# EFM32G8xx register map
File version: 2.7.3
CPU: CM3 r2p0, little endian, MPU, no FPU, 3 interrupt priority bits
Registers are 32-bit, read-write, reset 0x0 unless marked. A register's access mark holds for its fields unless they carry their own. Offsets are from the block's base; [hi:lo] are bit positions; {n}, {i} and the like mark numbered series.

## PRS
Base 0x400CC000
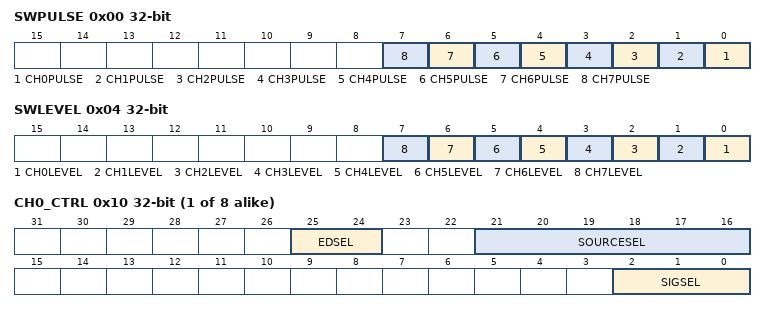
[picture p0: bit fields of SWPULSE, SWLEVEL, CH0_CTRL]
0x00 SWPULSE wo — Software Pulse Register
  [n] CH{n}PULSE (n=0..7) — Channel {n} Pulse Generation
0x04 SWLEVEL — Software Level Register
  [n] CH{n}LEVEL (n=0..7) — Channel {n} Software Level
{0x10+4i} CH{i}_CTRL (i=0..7) — Channel Control Register
  [25:24] EDSEL — Edge Detect Select
    0=OFF (Signal is left as it is); 1=POSEDGE (A one HFPERCLK cycle pulse is generated for every positive edge of the incoming signal); 2=NEGEDGE (A one HFPERCLK clock cycle pulse is generated for every negative edge of the incoming signal); 3=BOTHEDGES (A one HFPERCLK clock cycle pulse is generated for every edge of the incoming signal)
  [21:16] SOURCESEL — Source Select
    0=NONE (No source selected); 1=VCMP (Voltage Comparator); 2=ACMP0 (Analog Comparator 0); 3=ACMP1 (Analog Comparator 1); 6=DAC0 (Digital to Analog Converter 0); 8=ADC0 (Analog to Digital Converter 0); 16=USART0 (Universal Synchronous/Asynchronous Receiver/Transmitter 0); 17=USART1 (Universal Synchronous/Asynchronous Receiver/Transmitter 1); 18=USART2 (Universal Synchronous/Asynchronous Receiver/Transmitter 2); 28=TIMER0; 29=TIMER1; 30=TIMER2; 40=RTC (Real-Time Counter); 41=UART0 (Universal Asynchronous Receiver/Transmitter 0); 48=GPIOL (General purpose Input/Output); 49=GPIOH (General purpose Input/Output)
  [2:0] SIGSEL — Signal Select

## DAC0
Base 0x40004000
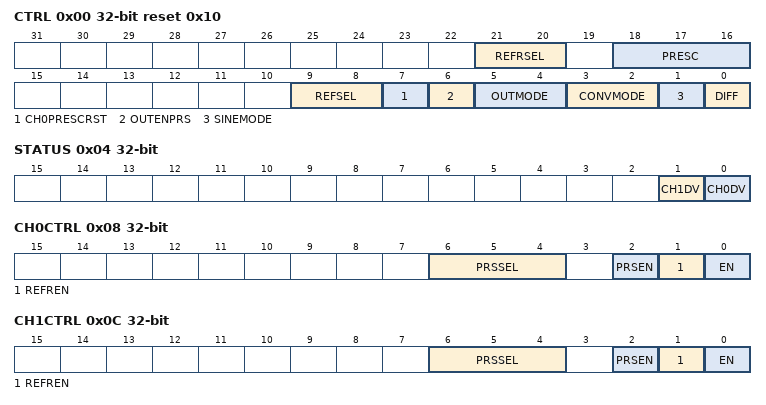
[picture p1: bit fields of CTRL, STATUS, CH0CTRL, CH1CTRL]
0x00 CTRL reset 0x10 — Control Register
  [21:20] REFRSEL — Refresh Interval Select
    0=8CYCLES (All channels with enabled refresh are refreshed every 8 prescaled cycles); 1=16CYCLES (All channels with enabled refresh are refreshed every 16 prescaled cycles); 2=32CYCLES (All channels with enabled refresh are refreshed every 32 prescaled cycles); 3=64CYCLES (All channels with enabled refresh are refreshed every 64 prescaled cycles)
  [18:16] PRESC — Prescaler Setting
    0=NODIVISION
  [9:8] REFSEL — Reference Selection
    0=1V25 (Internal 1.25 V bandgap reference); 1=2V5 (Internal 2.5 V bandgap reference); 2=VDD (VDD reference)
  [7] CH0PRESCRST — Channel 0 Start Reset Prescaler
  [6] OUTENPRS — PRS Controlled Output Enable
  [5:4] OUTMODE — Output Mode
    0=DISABLE (DAC output to pin and ADC disabled); 1=PIN (DAC output to pin enabled. DAC output to ADC disabled); 2=ADC (DAC output to pin disabled. DAC output to ADC enabled); 3=PINADC (DAC output to pin and ADC enabled)
  [3:2] CONVMODE — Conversion Mode
    0=CONTINUOUS (DAC is set in continuous mode); 1=SAMPLEHOLD (DAC is set in sample/hold mode); 2=SAMPLEOFF (DAC is set in sample/shut off mode)
  [1] SINEMODE
  [0] DIFF — Differential Mode
0x04 STATUS ro
  [1] CH1DV — Channel 1 Data Valid
  [0] CH0DV — Channel 0 Data Valid
0x08 CH0CTRL — Channel 0 Control Register
  [6:4] PRSSEL — Channel 0 PRS Trigger Select
    {v}=PRSCH{v} (PRS ch {v} triggers channel 0 conversion.) (v=0..7)
  [2] PRSEN — Channel 0 PRS Trigger Enable
  [1] REFREN — Channel 0 Automatic Refresh Enable
  [0] EN — Channel 0 Enable
0x0C CH1CTRL — Channel 1 Control Register
  [6:4] PRSSEL — Channel 1 PRS Trigger Select
    {v}=PRSCH{v} (PRS ch {v} triggers channel 1 conversion.) (v=0..7)
  [2] PRSEN — Channel 1 PRS Trigger Enable
  [1] REFREN — Channel 1 Automatic Refresh Enable
  [0] EN — Channel 1 Enable
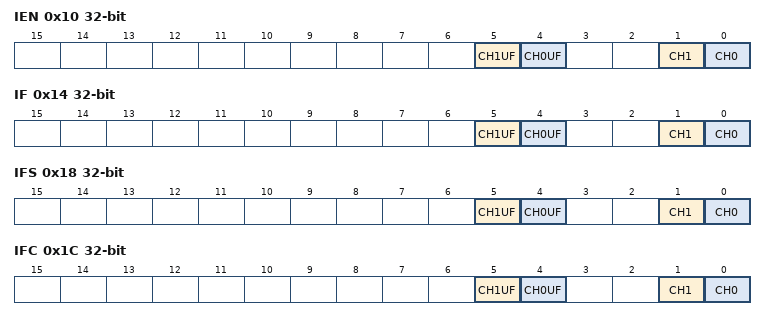
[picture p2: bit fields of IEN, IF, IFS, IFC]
0x10 IEN — Interrupt Enable Register
  [5] CH1UF — Channel 1 Conversion Data Underflow Interrupt Enable
  [4] CH0UF — Channel 0 Conversion Data Underflow Interrupt Enable
  [1] CH1 — Channel 1 Conversion Complete Interrupt Enable
  [0] CH0 — Channel 0 Conversion Complete Interrupt Enable
0x14 IF ro — Interrupt Flag Register
  [5] CH1UF — Channel 1 Data Underflow Interrupt Flag
  [4] CH0UF — Channel 0 Data Underflow Interrupt Flag
  [1] CH1 — Channel 1 Conversion Complete Interrupt Flag
  [0] CH0 — Channel 0 Conversion Complete Interrupt Flag
0x18 IFS wo — Interrupt Flag Set Register
  [5] CH1UF — Channel 1 Data Underflow Interrupt Flag Set
  [4] CH0UF — Channel 0 Data Underflow Interrupt Flag Set
  [1] CH1 — Channel 1 Conversion Complete Interrupt Flag Set
  [0] CH0 — Channel 0 Conversion Complete Interrupt Flag Set
0x1C IFC wo — Interrupt Flag Clear Register
  [5] CH1UF — Channel 1 Data Underflow Interrupt Flag Clear
  [4] CH0UF — Channel 0 Data Underflow Interrupt Flag Clear
  [1] CH1 — Channel 1 Conversion Complete Interrupt Flag Clear
  [0] CH0 — Channel 0 Conversion Complete Interrupt Flag Clear
0x20 CH0DATA — Channel 0 Data Register
  [11:0] DATA — Channel 0 Data
0x24 CH1DATA — Channel 1 Data Register
  [11:0] DATA — Channel 1 Data
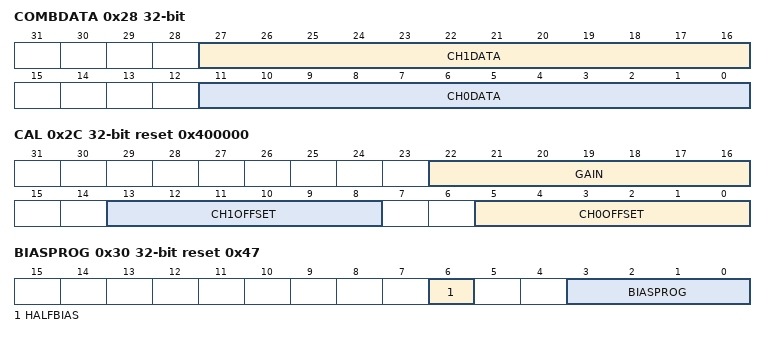
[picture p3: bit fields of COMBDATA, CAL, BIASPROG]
0x28 COMBDATA wo — Combined Data Register
  [27:16] CH1DATA — Channel 1 Data
  [11:0] CH0DATA — Channel 0 Data
0x2C CAL reset 0x400000 — Calibration Register
  [22:16] GAIN — Gain Calibration Value
  [13:8] CH1OFFSET — Channel 1 Offset Calibration Value
  [5:0] CH0OFFSET — Channel 0 Offset Calibration Value
0x30 BIASPROG reset 0x47 — Bias Programming Register
  [6] HALFBIAS — Half Bias Current
  [3:0] BIASPROG — Bias Programming Value

## Notices in the file
# License
Copyright 2020 Silicon Laboratories Inc. www.silabs.com
SPDX-License-Identifier: Zlib
The licensor of this software is Silicon Laboratories Inc.
This software is provided 'as-is', without any express or implied
warranty. In no event will the authors be held liable for any damages
arising from the use of this software.
Permission is granted to anyone to use this software for any purpose,
including commercial applications, and to alter it and redistribute it
freely, subject to the following restrictions:
1. The origin of this software must not be misrepresented; you must not
claim that you wrote the original software. If you use this software
in a product, an acknowledgment in the product documentation would be
appreciated but is not required.
2. Altered source versions must be plainly marked as such, and must not be
misrepresented as being the original software.
3. This notice may not be removed or altered from any source distribution.
